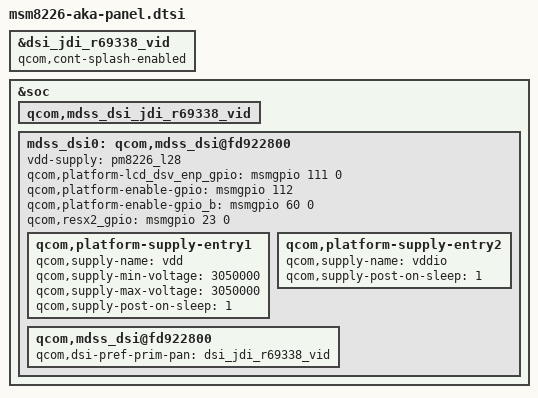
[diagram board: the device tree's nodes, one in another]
/* Copyright (c) 2013, Code Aurora Forum. All rights reserved.
 *
 * This program is free software; you can redistribute it and/or modify
 * it under the terms of the GNU General Public License version 2 and
 * only version 2 as published by the Free Software Foundation.
 *
 * This program is distributed in the hope that it will be useful,
 * but WITHOUT ANY WARRANTY; without even the implied warranty of
 * MERCHANTABILITY or FITNESS FOR A PARTICULAR PURPOSE.  See the
 * GNU General Public License for more details.
 */

&mdss_dsi0 {
	qcom,mdss_dsi@fd922800 {
		qcom,dsi-pref-prim-pan = <&dsi_jdi_r69338_vid>;
	};
};

&dsi_jdi_r69338_vid{
// To check kernel display function
// To check kernel display function
	qcom,cont-splash-enabled;
	status = "ok";
};

&soc {
       qcom,mdss_dsi_jdi_r69338_vid {
       status = "ok";
       };

	mdss_dsi0: qcom,mdss_dsi@fd922800 {
		vdd-supply = <&pm8226_l28>;
		qcom,platform-lcd_dsv_enp_gpio = <&msmgpio 111 0>;//DSV ENP
		qcom,platform-enable-gpio = <&msmgpio 112 0>;//DSV ENN.
		qcom,platform-enable-gpio_b = <&msmgpio 60 0>;//DSV ENN.
		qcom,resx2_gpio = <&msmgpio 23 0>;   // Rev.A only
		qcom,platform-supply-entry1 {
			qcom,supply-name = "vdd";
			qcom,supply-min-voltage = <3050000>;
			qcom,supply-max-voltage = <3050000>;
			qcom,supply-post-on-sleep = <1>;
		};
		qcom,platform-supply-entry2 {
			qcom,supply-name = "vddio";
			qcom,supply-post-on-sleep = <1>;
		};
	};

};
